# WS63 register map
File version: 1.0
CPU: other r0p0, little endian, MPU, FPU, 3 interrupt priority bits
Registers are 32-bit, read-write, reset 0x0 unless marked. A register's access mark holds for its fields unless they carry their own. Offsets are from the block's base; [hi:lo] are bit positions; {n}, {i} and the like mark numbered series.

## SYS_CTL1 — System Control 1 - Interrupt Controller
Base 0x44000000
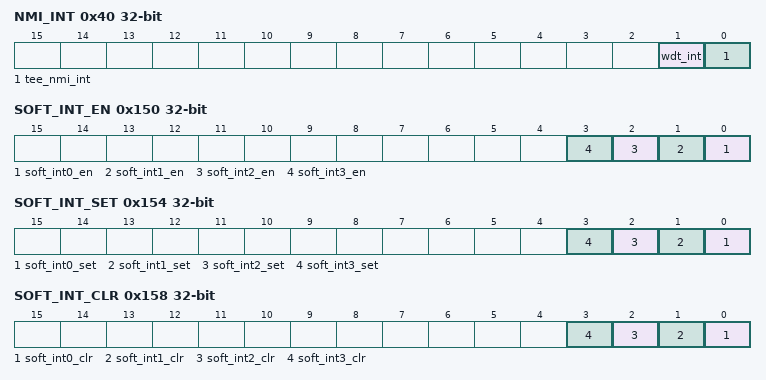
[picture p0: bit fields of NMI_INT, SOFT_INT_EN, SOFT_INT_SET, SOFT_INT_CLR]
0x40 NMI_INT — WDT interrupt query and NMI interrupt configuration register
  [1] wdt_int ro — Watchdog interrupt query. 0: WDT interrupt invalid; 1: WDT interrupt valid
  [0] tee_nmi_int — Software NMI interrupt configuration. 0: pull low CPU NMI soft interrupt; 1: pull high CPU NMI soft interrupt
0x150 SOFT_INT_EN — CPU soft interrupt enable register
  [n] soft_int{n}_en (n=0..3) — CPU soft interrupt {n} enable. 0: disabled; 1: enabled
0x154 SOFT_INT_SET wo — CPU soft interrupt set register (self-clearing)
  [n] soft_int{n}_set (n=0..3) — CPU soft interrupt {n} set. 0: no effect; 1: set effective
0x158 SOFT_INT_CLR wo — CPU soft interrupt clear register (self-clearing)
  [n] soft_int{n}_clr (n=0..3) — CPU soft interrupt {n} clear. 0: no effect; 1: clear effective
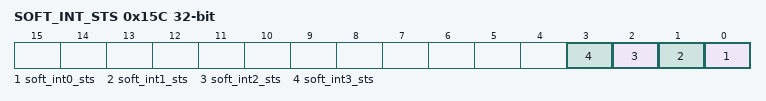
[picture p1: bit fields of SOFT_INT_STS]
0x15C SOFT_INT_STS ro — CPU soft interrupt status register
  [n] soft_int{n}_sts (n=0..3) — CPU soft interrupt {n} status. 0: no interrupt; 1: interrupt active
0x244 IP_AUTO_CG_BYPASS — IP auto clock-gate bypass control register. The vendor DMA porting path writes bit 19 so the primary DMA clock stays on during transfers.
  [19] dma_clk_on — DMA clock-on bypass bit used by DMA_CLK_AUTO_CTRL_REG/DMA_CLK_ON_MASK in the vendor SDK.

## GPIO0 — GPIO controller for GPIO[7:0]
Base 0x44028000
Same registers: GPIO1 0x44029000, GPIO2 0x4402A000, ULP_GPIO 0x57030000
0x00 GPIO_SW_OUT — GPIO data register
  [7:0] gpio_sw_out — GPIO data. Output: written value drives I/O; Input: reads external port
0x04 GPIO_SW_OEN reset 0xFF — GPIO data direction register
  [7:0] gpio_sw_oen — GPIO direction: 0=output; 1=input (default)
    0=Output direction; 1=Input direction
0x0C GPIO_INT_EN — GPIO interrupt enable register
  [7:0] gpio_int_en — Interrupt enable: 0=normal GPIO; 1=interrupt port
0x10 GPIO_INT_MASK — GPIO interrupt mask register
  [7:0] gpio_int_mask — Interrupt mask: 0=not masked; 1=masked
0x14 GPIO_INT_TYPE — GPIO interrupt type register
  [7:0] gpio_int_type — Interrupt type: 0=level; 1=edge
    0=Level-sensitive; 1=Edge-triggered
0x18 GPIO_INT_POLARITY — GPIO interrupt polarity register
  [7:0] gpio_int_polarity — Interrupt polarity: 0=low/falling; 1=high/rising
    0=LowFalling (Low level or falling edge); 1=HighRising (High level or rising edge)
0x1C GPIO_INT_DEDGE — GPIO dual-edge interrupt enable register
  [7:0] gpio_int_dedge — Dual-edge interrupt enable: 0=disabled; 1=enabled
    0=Disabled (Single-edge mode); 1=Enabled (Dual-edge triggered)
0x20 GPIO_INT_DEBOUNCE — GPIO interrupt debounce control register
  [7:0] gpio_int_debounce — Debounce enable: 0=disabled; 1=enabled
0x24 GPIO_INT_RAW — GPIO raw interrupt status register
  [7:0] gpio_int_raw ro — Raw interrupt status (before mask): 0=no interrupt; 1=interrupt
0x28 GPIO_INTR — GPIO interrupt status register
  [7:0] gpio_intr ro — Interrupt status (after mask): 0=no interrupt; 1=interrupt
0x2C GPIO_INT_EOI — GPIO interrupt clear register
  [7:0] gpio_int_eoi wo — Edge interrupt clear: 0=no clear; 1=clear interrupt
0x30 GPIO_DATA_SET
  [7:0] gpio_data_set wo — Write 1 to set corresponding GPIO_SW_OUT bits
0x34 GPIO_DATA_CLR — GPIO data clear register
  [7:0] gpio_data_clr wo — Write 1 to clear corresponding GPIO_SW_OUT bits

## I2C0 — I2C0 master controller
Base 0x44018000
Same registers: I2C1 0x44018100
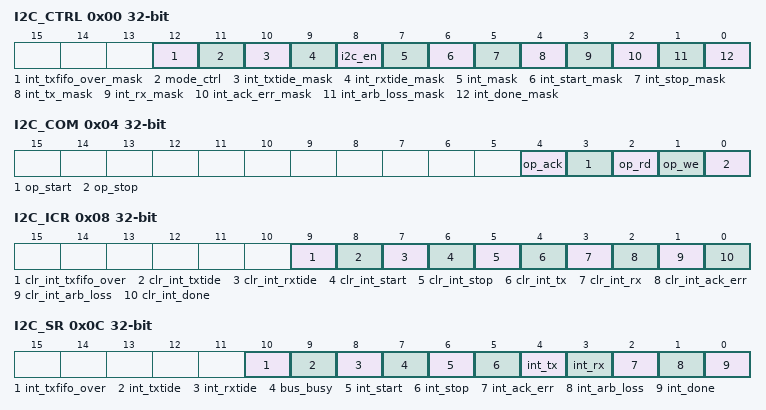
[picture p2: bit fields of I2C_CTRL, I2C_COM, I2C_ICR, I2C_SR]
0x00 I2C_CTRL — I2C control register
  [12] int_txfifo_over_mask — TX FIFO complete interrupt mask
  [11] mode_ctrl — I2C mode: 0=no FIFO; 1=FIFO mode
    0=No FIFO transfer mode; 1=FIFO (FIFO transfer mode)
  [10] int_txtide_mask — TX FIFO overflow interrupt mask
  [9] int_rxtide_mask — RX FIFO overflow interrupt mask
  [8] i2c_en — I2C enable: 0=disabled; 1=enabled
  [7] int_mask — I2C interrupt master mask
  [6] int_start_mask — Start condition interrupt mask
  [5] int_stop_mask — Stop condition interrupt mask
  [4] int_tx_mask — TX interrupt mask
  [3] int_rx_mask — RX interrupt mask
  [2] int_ack_err_mask — ACK error interrupt mask
  [1] int_arb_loss_mask — Arbitration loss interrupt mask
  [0] int_done_mask — Transfer complete interrupt mask: 0=masked; 1=unmasked
0x04 I2C_COM — I2C command register
  [4] op_ack — Master RX ACK: 0=send ACK; 1=no ACK
  [3] op_start — Generate start condition
  [2] op_rd — Generate read operation
  [1] op_we — Generate write operation
  [0] op_stop — Generate stop condition: 0=end; 1=active
0x08 I2C_ICR — I2C interrupt clear register
  [9] clr_int_txfifo_over wo — Clear TX FIFO complete interrupt
  [8] clr_int_txtide wo — Clear TX FIFO overflow interrupt
  [7] clr_int_rxtide wo — Clear RX FIFO overflow interrupt
  [6] clr_int_start wo — Clear start interrupt
  [5] clr_int_stop wo — Clear stop interrupt
  [4] clr_int_tx wo — Clear TX interrupt
  [3] clr_int_rx wo — Clear RX interrupt
  [2] clr_int_ack_err wo — Clear ACK error interrupt
  [1] clr_int_arb_loss wo — Clear arbitration loss interrupt
  [0] clr_int_done wo — Clear transfer complete interrupt
0x0C I2C_SR — I2C status register
  [10] int_txfifo_over ro — TX FIFO complete flag
  [9] int_txtide ro — TX FIFO overflow flag
  [8] int_rxtide ro — RX FIFO overflow flag
  [7] bus_busy ro — Bus busy: 0=idle; 1=busy
  [6] int_start ro — Start interrupt flag
  [5] int_stop ro — Stop interrupt flag
  [4] int_tx ro — TX interrupt flag
  [3] int_rx ro — RX interrupt flag
  [2] int_ack_err ro — ACK error interrupt flag
  [1] int_arb_loss ro — Arbitration loss interrupt flag
  [0] int_done ro — Transfer complete interrupt flag
0x10 I2C_SCL_H — SCL high period register [Constraint: write only when I2C_CTRL[int_mask]=0]
  [15:0] scl_h — SCL high period (value*2 = actual period)
0x14 I2C_SCL_L — SCL low period register [Constraint: write only when I2C_CTRL[int_mask]=0]
  [15:0] scl_l — SCL low period (value*2 = actual period)
0x18 I2C_TXR — I2C TX data register
  [7:0] i2c_txr — TX data byte
0x1C I2C_RXR — I2C RX data register
  [7:0] i2c_rxr ro — RX data byte
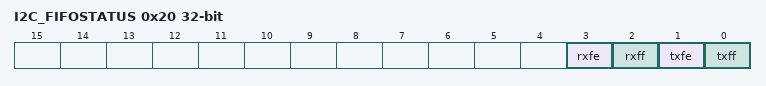
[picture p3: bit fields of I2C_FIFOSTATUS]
0x20 I2C_FIFOSTATUS — FIFO status register
  [3] rxfe ro — RX FIFO empty
  [2] rxff ro — RX FIFO full
  [1] txfe ro — TX FIFO empty: 0=not empty; 1=empty
  [0] txff ro — TX FIFO full: 0=not full; 1=full
0x24 I2C_TXCOUNT — TX FIFO count register
  [5:0] txcount — TX FIFO character count (write any value to clear TX FIFO)
0x28 I2C_RXCOUNT — RX FIFO count register
  [5:0] rxcount — RX FIFO character count (write any value to clear RX FIFO)
0x2C I2C_RXTIDE reset 0x1 — RX FIFO threshold register
  [5:0] rxtide — RX FIFO overflow interrupt trigger value
0x30 I2C_TXTIDE reset 0x1 — TX FIFO threshold register
  [5:0] txtide — TX FIFO overflow interrupt trigger value
0x34 I2C_FTRPER reset 0xF — Glitch filter configuration register
  [3:0] ftrper — Glitch filter period in ic_clk cycles
